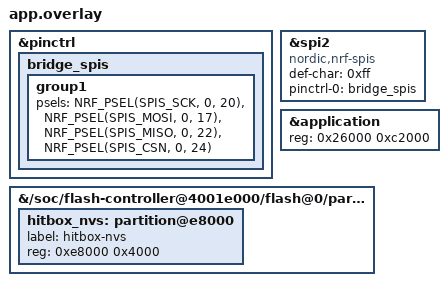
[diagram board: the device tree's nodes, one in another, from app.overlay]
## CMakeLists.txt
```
cmake_minimum_required(VERSION 3.20)
find_package(Zephyr REQUIRED HINTS $ENV{ZEPHYR_BASE})
project(console_rx_bridge)
target_include_directories(app PRIVATE ../common src)
target_sources(app PRIVATE src/main.c src/spi.c src/link.c src/receiver.c ../common/air.c)

target_sources(app PRIVATE ../common/match.c ../common/match_usb.c)
```

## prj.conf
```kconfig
CONFIG_ESB=y
CONFIG_ENTROPY_GENERATOR=y
CONFIG_ENTROPY_DEVICE_RANDOM_GENERATOR=y
CONFIG_NRFX_SPIS2=y
CONFIG_NRFX_GPIOTE0=y
CONFIG_CONSOLE=n
CONFIG_SERIAL=n
CONFIG_LOG=n

CONFIG_FLASH=y
CONFIG_FLASH_MAP=y
CONFIG_FLASH_PAGE_LAYOUT=y
CONFIG_NVS=y
CONFIG_NVS_DATA_CRC=y
CONFIG_ESB_TX_FIFO_SIZE=32
CONFIG_ESB_RX_FIFO_SIZE=32

CONFIG_USB_DEVICE_STACK=y
CONFIG_USB_SELF_POWERED=n
CONFIG_USB_DEVICE_PID=0x0008
CONFIG_USB_DEVICE_VID=0x1209
CONFIG_USB_DEVICE_PRODUCT="Console RX setup"
```

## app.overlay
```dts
/* SPDX-License-Identifier: MIT */
&pinctrl {
	bridge_spis: bridge_spis {
		group1 {
			psels = <NRF_PSEL(SPIS_SCK, 0, 20)>, <NRF_PSEL(SPIS_MOSI, 0, 17)>,
			        <NRF_PSEL(SPIS_MISO, 0, 22)>, <NRF_PSEL(SPIS_CSN, 0, 24)>;
		};
	};
};
&spi2 {
	compatible = "nordic,nrf-spis";
	status = "okay";
	def-char = <0xff>;
	pinctrl-0 = <&bridge_spis>;
	pinctrl-names = "default";
};

/* Keep the original bootloader storage untouched. Carve NVS from our app area. */
&application { reg = <0x26000 0xc2000>; };
&{/soc/flash-controller@4001e000/flash@0/partitions} {
    hitbox_nvs: partition@e8000 { label = "hitbox-nvs"; reg = <0xe8000 0x4000>; };
};
```

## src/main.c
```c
/* SPDX-License-Identifier: MIT */
#include <zephyr/kernel.h>
#include "air.h"
#include "match_usb.h"
#include "spi.h"
#include "link.h"

int main(void)
{
	struct link link;
	link_init(&link, air_nonce);
	match_init(CONSOLE_RX);
	int rc = match_usb_open(0);
	if (rc) return rc;
	rc = air_start(true);
	if (rc) return rc;
	rc = spi_init();
	if (rc) return rc;
	struct gp_frame reply = link_spi(&link, NULL, k_uptime_get_32());
	rc = spi_arm(&reply);
	while (!rc) {
		uint32_t ms = k_uptime_get_32();
		link_tick(&link, ms);
		struct gp_frame f;
		while (air_receive(&f)) {
			if (f.type == GP_STATUS || f.type == GP_OFFER) continue;
			reply = link_rf(&link, &f, ms);
			air_send(&reply);
		}
		int count = spi_take(&f);
		if (count) {
			reply = link_spi(&link, count > 0 ? &f : NULL, ms);
			rc = spi_arm(&reply);
		}
		match_usb_service();
		k_sleep(K_USEC(100));
	}
	return rc;
}
```

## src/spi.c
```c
/* SPDX-License-Identifier: MIT */
#include "spi.h"
#include <zephyr/kernel.h>
#include <nrfx_spis.h>
#include <nrfx_gpiote.h>
#include <nrfx_ppi.h>
#include <hal/nrf_gpio.h>
#include <hal/nrf_gpiote.h>

enum { SCK = 20, MOSI = 17, MISO = 22, CS = 24, READY = 32 };
static const nrfx_spis_t device = NRFX_SPIS_INSTANCE(2);
static const nrfx_gpiote_t gpio_events = NRFX_GPIOTE_INSTANCE(0);
static uint8_t clear_on_cs, ready_task;
static struct {
	uint8_t tx[GP_WIRE_SIZE] __aligned(4);
	uint8_t rx[GP_WIRE_SIZE + 1] __aligned(4);
} dma[2];
static unsigned bank;
static atomic_t wait_cs_high;
static atomic_t received; /* 0 waiting, otherwise byte count + 1 */

static void event(const nrfx_spis_evt_t *e, void *context)
{
	ARG_UNUSED(context);
	if (e->evt_type == NRFX_SPIS_BUFFERS_SET_DONE) {
		if (nrf_gpio_pin_read(CS)) NRF_GPIOTE->TASKS_SET[ready_task] = 1;
		else atomic_set(&wait_cs_high, 1);
	} else if (e->evt_type == NRFX_SPIS_XFER_DONE) {
		atomic_clear(&wait_cs_high);
		atomic_set(&received, 1 + e->rx_amount);
	}
}

int spi_init(void)
{
	nrf_ppi_channel_t ppi;
	if (nrfx_gpiote_channel_alloc(&gpio_events, &clear_on_cs) ||
	    nrfx_gpiote_channel_alloc(&gpio_events, &ready_task) ||
	    nrfx_ppi_channel_alloc(&ppi)) return -ENOMEM;
	nrf_gpio_pin_clear(READY);
	nrf_gpio_cfg_output(READY);
	nrfx_spis_config_t cfg = NRFX_SPIS_DEFAULT_CONFIG(SCK, MOSI, MISO, CS);
	cfg.csn_pullup = NRF_GPIO_PIN_PULLUP;
	cfg.irq_priority = 3;
	IRQ_CONNECT(SPIM2_SPIS2_SPI2_IRQn, 3,
		    nrfx_spis_2_irq_handler, NULL, 0);
	if (nrfx_spis_init(&device, &cfg, event, NULL)) return -EIO;
	nrf_gpiote_event_configure(NRF_GPIOTE, clear_on_cs, CS, NRF_GPIOTE_POLARITY_HITOLO);
	nrf_gpiote_event_enable(NRF_GPIOTE, clear_on_cs);
	nrf_gpiote_task_configure(NRF_GPIOTE, ready_task, READY, NRF_GPIOTE_POLARITY_TOGGLE,
				  NRF_GPIOTE_INITIAL_VALUE_LOW);
	nrf_gpiote_task_enable(NRF_GPIOTE, ready_task);
	if (nrfx_ppi_channel_assign(ppi, (uint32_t)&NRF_GPIOTE->EVENTS_IN[clear_on_cs],
				   (uint32_t)&NRF_GPIOTE->TASKS_CLR[ready_task]) ||
	    nrfx_ppi_channel_enable(ppi)) return -EIO;
	return 0;
}

int spi_arm(const struct gp_frame *reply)
{
	bank ^= 1;
	if (!gp_encode(dma[bank].tx, GP_WIRE_SIZE, reply)) return -EINVAL;
	return nrfx_spis_buffers_set(&device, dma[bank].tx, sizeof(dma[bank].tx),
				     dma[bank].rx, sizeof(dma[bank].rx)) ? -EIO : 0;
}

int spi_take(struct gp_frame *frame)
{
	/* A master may hold CS low at power-up. Advertise this buffer once
	 * after release; a subsequent falling edge still clears READY in hardware. */
	unsigned int key = irq_lock();
	if (atomic_get(&wait_cs_high) && nrf_gpio_pin_read(CS)) {
		atomic_clear(&wait_cs_high);
		NRF_GPIOTE->TASKS_SET[ready_task] = 1;
	}
	atomic_val_t count = atomic_set(&received, 0);
	irq_unlock(key);
	if (!count) return 0;
	return gp_decode(frame, dma[bank].rx, count - 1) ? 1 : -1;
}

void match_prepare_boot(void)
{
    irq_disable(SPIM2_SPIS2_SPI2_IRQn);
    NRF_GPIOTE->TASKS_CLR[ready_task]=1;
    nrfx_spis_uninit(&device);
}
```

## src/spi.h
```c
/* SPDX-License-Identifier: MIT */
#ifndef BRIDGE_SPI_H
#define BRIDGE_SPI_H
#include "protocol.h"
int spi_init(void);
int spi_arm(const struct gp_frame *reply);
/* One transaction: 1 valid, -1 malformed, 0 still armed. */
int spi_take(struct gp_frame *frame);
#endif
```
